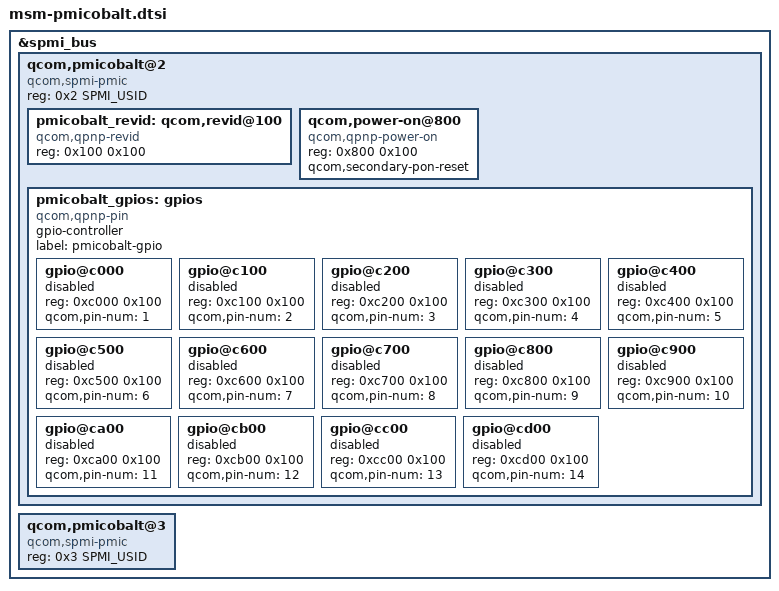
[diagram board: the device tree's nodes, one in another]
/* Copyright (c) 2016, The Linux Foundation. All rights reserved.
 *
 * This program is free software; you can redistribute it and/or modify
 * it under the terms of the GNU General Public License version 2 and
 * only version 2 as published by the Free Software Foundation.
 *
 * This program is distributed in the hope that it will be useful,
 * but WITHOUT ANY WARRANTY; without even the implied warranty of
 * MERCHANTABILITY or FITNESS FOR A PARTICULAR PURPOSE.  See the
 * GNU General Public License for more details.
 */

#include <dt-bindings/interrupt-controller/irq.h>
#include <dt-bindings/spmi/spmi.h>

&spmi_bus {
	qcom,pmicobalt@2 {
		compatible = "qcom,spmi-pmic";
		reg = <0x2 SPMI_USID>;
		#address-cells = <2>;
		#size-cells = <0>;

		pmicobalt_revid: qcom,revid@100 {
			compatible = "qcom,qpnp-revid";
			reg = <0x100 0x100>;
		};

		qcom,power-on@800 {
			compatible = "qcom,qpnp-power-on";
			reg = <0x800 0x100>;
			qcom,secondary-pon-reset;
		};

		pmicobalt_gpios: gpios {
			compatible = "qcom,qpnp-pin";
			gpio-controller;
			#gpio-cells = <2>;
			#address-cells = <1>;
			#size-cells = <1>;
			label = "pmicobalt-gpio";

			gpio@c000 {
				reg = <0xc000 0x100>;
				qcom,pin-num = <1>;
				status = "disabled";
			};

			gpio@c100 {
				reg = <0xc100 0x100>;
				qcom,pin-num = <2>;
				status = "disabled";
			};

			gpio@c200 {
				reg = <0xc200 0x100>;
				qcom,pin-num = <3>;
				status = "disabled";
			};

			gpio@c300 {
				reg = <0xc300 0x100>;
				qcom,pin-num = <4>;
				status = "disabled";
			};

			gpio@c400 {
				reg = <0xc400 0x100>;
				qcom,pin-num = <5>;
				status = "disabled";
			};

			gpio@c500 {
				reg = <0xc500 0x100>;
				qcom,pin-num = <6>;
				status = "disabled";
			};

			gpio@c600 {
				reg = <0xc600 0x100>;
				qcom,pin-num = <7>;
				status = "disabled";
			};

			gpio@c700 {
				reg = <0xc700 0x100>;
				qcom,pin-num = <8>;
				status = "disabled";
			};

			gpio@c800 {
				reg = <0xc800 0x100>;
				qcom,pin-num = <9>;
				status = "disabled";
			};

			gpio@c900 {
				reg = <0xc900 0x100>;
				qcom,pin-num = <10>;
				status = "disabled";
			};

			gpio@ca00 {
				reg = <0xca00 0x100>;
				qcom,pin-num = <11>;
				status = "disabled";
			};

			gpio@cb00 {
				reg = <0xcb00 0x100>;
				qcom,pin-num = <12>;
				status = "disabled";
			};

			gpio@cc00 {
				reg = <0xcc00 0x100>;
				qcom,pin-num = <13>;
				status = "disabled";
			};

			gpio@cd00 {
				reg = <0xcd00 0x100>;
				qcom,pin-num = <14>;
				status = "disabled";
			};
		};
	};

	qcom,pmicobalt@3 {
		compatible ="qcom,spmi-pmic";
		reg = <0x3 SPMI_USID>;
		#address-cells = <2>;
		#size-cells = <0>;
	};
};
